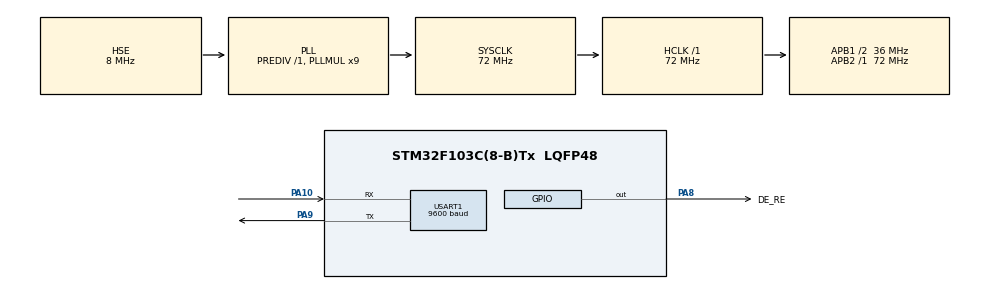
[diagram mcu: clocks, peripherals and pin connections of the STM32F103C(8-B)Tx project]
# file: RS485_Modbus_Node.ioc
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Mcu.Family=STM32F1
Mcu.Name=STM32F103C(8-B)Tx
Mcu.Package=LQFP48
NVIC.PriorityGroup=NVIC_PRIORITYGROUP_4
NVIC.TIM2_IRQn=true\:0\:0\:false\:false\:true\:true\:true\:true
NVIC.USART1_IRQn=true\:0\:0\:false\:false\:true\:true\:true\:true
PA10.Mode=Asynchronous
PA10.Signal=USART1_RX
PA13.Mode=Serial_Wire
PA13.Signal=SYS_JTMS-SWDIO
PA14.Mode=Serial_Wire
PA14.Signal=SYS_JTCK-SWCLK
PA8.GPIO_Label=DE_RE
PA8.Signal=GPIO_Output
PA9.Mode=Asynchronous
PA9.Signal=USART1_TX
PD0-OSC_IN.Mode=HSE-External-Oscillator
PD0-OSC_IN.Signal=RCC_OSC_IN
PD1-OSC_OUT.Mode=HSE-External-Oscillator
PD1-OSC_OUT.Signal=RCC_OSC_OUT
ProjectManager.HeapSize=0x200
ProjectManager.StackSize=0x400
ProjectManager.TargetToolchain=MDK-ARM V5.32
RCC.AHBFreq_Value=72000000
RCC.APB1CLKDivider=RCC_HCLK_DIV2
RCC.APB1Freq_Value=36000000
RCC.APB1TimFreq_Value=72000000
RCC.APB2Freq_Value=72000000
RCC.APB2TimFreq_Value=72000000
RCC.HCLKFreq_Value=72000000
RCC.PLLMUL=RCC_PLL_MUL9
RCC.PLLSourceVirtual=RCC_PLLSOURCE_HSE
RCC.SYSCLKFreq_VALUE=72000000
RCC.SYSCLKSource=RCC_SYSCLKSOURCE_PLLCLK
RCC.USBFreq_Value=72000000
TIM2.AutoReloadPreload=TIM_AUTORELOAD_PRELOAD_ENABLE
TIM2.Period=36
TIM2.Prescaler=7199
USART1.BaudRate=9600
USART1.VirtualMode=VM_ASYNC
VP_TIM2_VS_ClockSourceINT.Mode=Internal
board=custom

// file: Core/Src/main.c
/* USER CODE BEGIN Header */
/**
  ******************************************************************************
  * @file           : main.c
  * @brief          : Main program body
  ******************************************************************************
  * @attention
  *
  * Copyright (c) 2026 STMicroelectronics.
  * All rights reserved.
  *
  * This software is licensed under terms that can be found in the LICENSE file
  * in the root directory of this software component.
  * If no LICENSE file comes with this software, it is provided AS-IS.
  *
  ******************************************************************************
  */
/* USER CODE END Header */
#include "main.h"
#include "tim.h"
#include "usart.h"
#include "gpio.h"

/* USER CODE BEGIN Includes */
#include "rs485_phy.h"
/* USER CODE END Includes */

void SystemClock_Config(void);

/* USER CODE BEGIN 0 */
/**
 * @brief Hàm xu lý nhan khung tin kiem thu (Test Echo):
 *        Khi nhan duoc 1 khung du lieu hoàn chinh qua RS485,
 *        vi dieu khien se gui nguoc lai y nguyên khung du lieu dó ra bus.
 */
void Test_EchoCallback(uint8_t *data, uint16_t length)
{
    RS485_Send(data, length);
}
/* USER CODE END 0 */

int main(void)
{

  /* MCU Configuration--------------------------------------------------------*/

  /* Reset of all peripherals, Initializes the Flash interface and the Systick. */
  HAL_Init();

  /* Configure the system clock */
  SystemClock_Config();

  /* Initialize all configured peripherals */
  MX_GPIO_Init();
  MX_TIM2_Init();
  MX_USART1_UART_Init();
  /* USER CODE BEGIN 2 */
	// 1. Khoi tao tang vat lý RS485 voi USART1, TIM2, và chân dieu khien DE/RE
RS485_Init(&huart1, &htim2, DE_RE_GPIO_Port, DE_RE_Pin);
// 2. Ðang ký hàm Echo de kiem the tang truyen thông
RS485_RegisterCallback(Test_EchoCallback);
  /* USER CODE END 2 */

  /* Infinite loop */
  while (1)
  {

  }
}

void SystemClock_Config(void)
{
  RCC_OscInitTypeDef RCC_OscInitStruct = {0};
  RCC_ClkInitTypeDef RCC_ClkInitStruct = {0};

  /** Initializes the RCC Oscillators according to the specified parameters
  * in the RCC_OscInitTypeDef structure.
  */
  RCC_OscInitStruct.OscillatorType = RCC_OSCILLATORTYPE_HSE;
  RCC_OscInitStruct.HSEState = RCC_HSE_ON;
  RCC_OscInitStruct.HSEPredivValue = RCC_HSE_PREDIV_DIV1;
  RCC_OscInitStruct.HSIState = RCC_HSI_ON;
  RCC_OscInitStruct.PLL.PLLState = RCC_PLL_ON;
  RCC_OscInitStruct.PLL.PLLSource = RCC_PLLSOURCE_HSE;
  RCC_OscInitStruct.PLL.PLLMUL = RCC_PLL_MUL9;
  if (HAL_RCC_OscConfig(&RCC_OscInitStruct) != HAL_OK)
  {
    Error_Handler();
  }

  /** Initializes the CPU, AHB and APB buses clocks
  */
  RCC_ClkInitStruct.ClockType = RCC_CLOCKTYPE_HCLK|RCC_CLOCKTYPE_SYSCLK
                              |RCC_CLOCKTYPE_PCLK1|RCC_CLOCKTYPE_PCLK2;
  RCC_ClkInitStruct.SYSCLKSource = RCC_SYSCLKSOURCE_PLLCLK;
  RCC_ClkInitStruct.AHBCLKDivider = RCC_SYSCLK_DIV1;
  RCC_ClkInitStruct.APB1CLKDivider = RCC_HCLK_DIV2;
  RCC_ClkInitStruct.APB2CLKDivider = RCC_HCLK_DIV1;

  if (HAL_RCC_ClockConfig(&RCC_ClkInitStruct, FLASH_LATENCY_2) != HAL_OK)
  {
    Error_Handler();
  }
}

/* USER CODE BEGIN 4 */
void HAL_UART_RxCpltCallback(UART_HandleTypeDef *huart) {
    if (huart->Instance == USART1) {
        RS485_UART_RxByteCallback();// Chuyen tiep su kien sang module RS485
    }
}

void HAL_UART_TxCpltCallback(UART_HandleTypeDef *huart) {
    if (huart->Instance == USART1) {
        RS485_UART_TxCpltCallback();// Chuyen tiep su kien de ha chân DE/RE
    }
}

void HAL_TIM_PeriodElapsedCallback(TIM_HandleTypeDef *htim) {
    if (htim->Instance == TIM2) {
        RS485_Timer_PeriodElapsedCallback();// Báo ket thúc khung tin (timeout 3.5 ký tu)
    }
}
void HAL_UART_ErrorCallback(UART_HandleTypeDef *huart) {
    if (huart->Instance == USART1) {
        RS485_UART_ErrorCallback();// Xóa co loi và kích hoat lai ngat nhan
    }
}
/* USER CODE END 4 */

void Error_Handler(void)
{
  __disable_irq();
  while (1)
  {
  }
}
